# STM32WB1Mxx register map
File version: 1.0
Registers are 32-bit, read-write, reset 0x0 unless marked. A register's access mark holds for its fields unless they carry their own. Offsets are from the block's base; [hi:lo] are bit positions; {n}, {i} and the like mark numbered series.

## IWDG — Independent WATCHDOG
Base 0x40003000
0x00 KR — IWDG Key register
  [15:0] KEY — Key value (write only, read 0000h)
0x04 PR — IWDG Prescaler register
  [2:0] PR — PR[2:0] (Prescaler divider)
0x08 RLR — IWDG Reload register
  [11:0] RL — Watchdog counter reload value
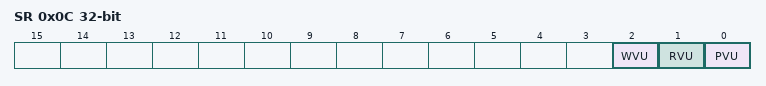
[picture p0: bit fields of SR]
0x0C SR — IWDG Status register
  [2] WVU — Watchdog counter window value update
  [1] RVU — Watchdog counter reload value update
  [0] PVU — Watchdog prescaler value update
0x10 WINR — IWDG Window register
  [11:0] WIN — Watchdog counter window value

## COMP1 — Comparator
Base 0x40010200
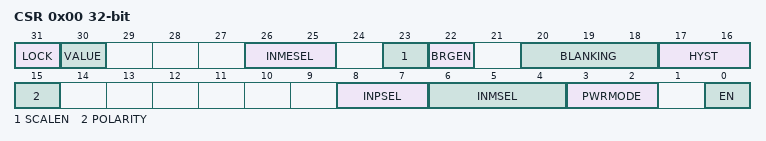
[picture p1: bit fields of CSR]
0x00 CSR — COMP control and status register
  [31] LOCK — Comparator lock
  [30] VALUE — Comparator output level
  [26:25] INMESEL — Comparator input minus extended selection
  [23] SCALEN — Comparator scaler bridge enable
  [22] BRGEN — Comparator voltage scaler enable
  [20:18] BLANKING — Comparator blanking source
    0=NONE (Comparator output without blanking); 1=TIM1_OC5 (Comparator output blanking source TIM1 OC5 (common to all COMP instances: COMP1, COMP2)); 2=TIM2_OC3 (Comparator output blanking source TIM2 OC3 (common to all COMP instances: COMP1, COMP2))
  [17:16] HYST — Comparator hysteresis
    0=NONE (No hysteresis); 1=LOW (Hysteresis level low); 2=MEDIUM (Hysteresis level medium); 3=HIGH (Hysteresis level high)
  [15] POLARITY — Comparator output polarity
    0=NONINVERTED (COMP output polarity is not inverted: comparator output is high when the plus (non-inverting) input is at a higher voltage than the minus (inverting) input); 1=INVERTED (COMP output polarity is inverted: comparator output is low when the plus (non-inverting) input is at a lower voltage than the minus (inverting) input)
  [8:7] INPSEL — Comparator input plus selection
    1=IO2 (Comparator input plus connected to IO2 (pin PB2 for COMP1, pin PB6 for COMP2)); 2=IO3 (Comparator input plus connected to IO3 (pin PA1 for COMP1, pin PA3 for COMP2))
  [6:4] INMSEL — Comparator input minus selection
  [3:2] PWRMODE — Comparator power mode
    0=HIGHSPEED (COMP power mode to high speed); 1=MEDIUMSPEED (COMP power mode to medium speed); 3=ULTRALOWPOWER (COMP power mode to ultra-low power)
  [0] EN — Comparator enable

## SPI1 — Serial Peripheral Interface
Base 0x40013000
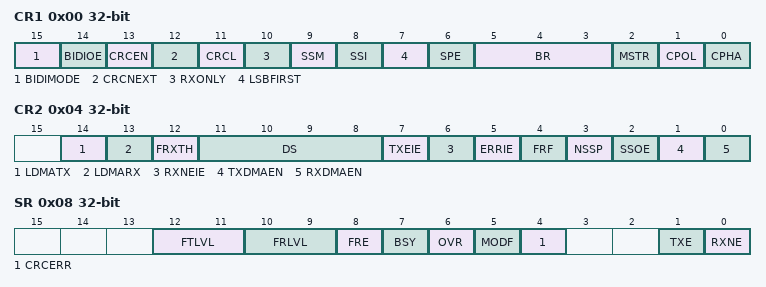
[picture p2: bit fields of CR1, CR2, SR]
0x00 CR1 — SPI Control register 1
  [15] BIDIMODE — Bidirectional data mode enable
  [14] BIDIOE — Output enable in bidirectional mode
  [13] CRCEN — Hardware CRC calculation enable
  [12] CRCNEXT — Transmit CRC next
  [11] CRCL — CRC Length
    0=CRC_8BIT (8-bit CRC length); 1=CRC_16BIT (16-bit CRC length)
  [10] RXONLY — Receive only
  [9] SSM — Software slave management
  [8] SSI — Internal slave select
  [7] LSBFIRST — Frame Format
    1=LSB_FIRST (Data is transmitted/received with the LSB first); 0=MSB_FIRST (Data is transmitted/received with the MSB first)
  [6] SPE — SPI Enable
  [5:3] BR — BR[2:0] bits (Baud Rate Control)
    0=DIV2 (BaudRate control equal to fPCLK/2); 1=DIV4 (BaudRate control equal to fPCLK/4); 2=DIV8 (BaudRate control equal to fPCLK/8); 3=DIV16 (BaudRate control equal to fPCLK/16); 4=DIV32 (BaudRate control equal to fPCLK/32); 5=DIV64 (BaudRate control equal to fPCLK/64); 6=DIV128 (BaudRate control equal to fPCLK/128); 7=DIV256 (BaudRate control equal to fPCLK/256)
  [2] MSTR — Master Selection
  [1] CPOL — Clock Polarity
    0=LOW (Clock to 0 when idle); 1=HIGH (Clock to 1 when idle)
  [0] CPHA — Clock Phase
    0=PHASE_1EDGE (First clock transition is the first data capture edge); 1=PHASE_2EDGE (Second clock transition is the first data capture edge)
0x04 CR2 — SPI Control register 2
  [14] LDMATX — Last DMA transfer for transmission
  [13] LDMARX — Last DMA transfer for reception
  [12] FRXTH — FIFO reception Threshold
    0=HALF (RXNE event is generated if FIFO level is greater than or equal to 1/2 (16-bit)); 1=QUARTER (RXNE event is generated if FIFO level is greater than or equal to 1/4 (8-bit))
  [11:8] DS — DS[3:0] Data Size
    {v}=DATAWIDTH_{v+1}BIT (Data length for SPI transfer: {v+1} bits) (v=3..15)
  [7] TXEIE — Tx buffer Empty Interrupt Enable
  [6] RXNEIE — RX buffer Not Empty Interrupt Enable
  [5] ERRIE — Error Interrupt Enable
  [4] FRF — Frame Format Enable
    0=MOTOROLA (Motorola mode. Used as default value); 1=TI (TI mode)
  [3] NSSP — NSS pulse management Enable
  [2] SSOE — SS Output Enable
  [1] TXDMAEN — Tx Buffer DMA Enable
  [0] RXDMAEN — Rx Buffer DMA Enable
0x08 SR — SPI Status register
  [12:11] FTLVL — FIFO Transmission Level
    0=EMPTY (FIFO transmission empty); 1=QUARTER_FULL (FIFO transmission 1/4); 2=HALF_FULL (FIFO transmission 1/2); 3=FULL (FIFO transmission full)
  [10:9] FRLVL — FIFO Reception Level
    0=EMPTY (FIFO reception empty); 1=QUARTER_FULL (FIFO reception 1/4); 2=HALF_FULL (FIFO reception 1/2); 3=FULL (FIFO reception full)
  [8] FRE — TI frame format error
  [7] BSY — Busy flag
  [6] OVR — Overrun flag
  [5] MODF — Mode fault
  [4] CRCERR — CRC Error flag
  [1] TXE — Transmit buffer Empty
  [0] RXNE — Receive buffer Not Empty
0x0C DR — SPI data register
  [15:0] DR — Data Register
0x10 CRCPR — SPI CRC polynomial register
  [15:0] CRCPOLY — CRC polynomial register
0x14 RXCRCR — SPI Rx CRC register
  [15:0] RXCRC
0x18 TXCRCR — SPI Tx CRC register
  [15:0] TXCRC
